# f280015x_epg_mux_regs register map
Vendor: Texas Instruments
Peripheral module from a debugger description file (folder C2000).
Address unit: 16 bits
Registers are 32-bit, read-write, no defined reset value unless marked. A register's access mark holds for its fields unless they carry their own. Offsets are as the file gives them; lines under a group give offsets from that group; [hi:lo] are bit positions; {n}, {i} and the like mark numbered series; 'fields as' and 'values as' point back to an identical list; <NAME> marks a mode.

## EPG_MUX_REGS — EPG MUX Registers
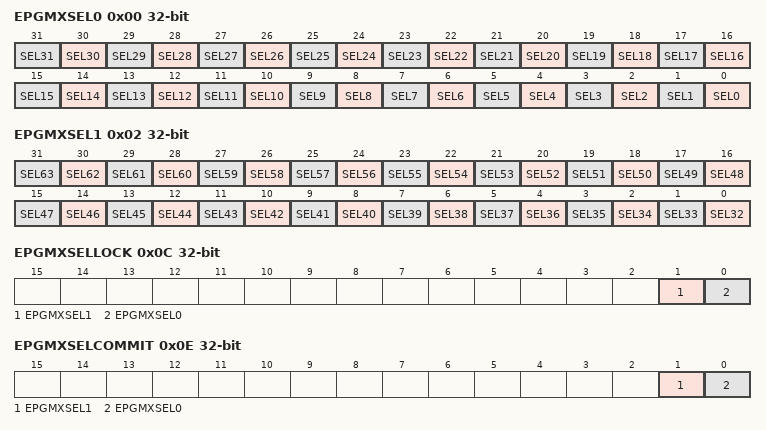
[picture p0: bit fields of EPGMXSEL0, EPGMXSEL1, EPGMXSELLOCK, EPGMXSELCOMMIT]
0x00 EPGMXSEL0 — EPG Mux select register 0
  [n] SEL{n} (n=0..31) — DATAOUT[{n}] mux select.
0x02 EPGMXSEL1 — EPG Mux select register 1
  [n-32] SEL{n} (n=32..63) — DATAOUT[{n}] mux select.
0x0C EPGMXSELLOCK — EPG Mux select register lock
  [1] EPGMXSEL1 — EPGMXSEL1 lock bit
  [0] EPGMXSEL0 — EPGMXSEL0 lock bit
0x0E EPGMXSELCOMMIT — EPG Mux select register commit
  [1] EPGMXSEL1 — EPGMXSEL1 commit bit
  [0] EPGMXSEL0 — EPGMXSEL0 commit bit
